VERSION ""

NS_ :

BS_ :

BU_: Charger BMS

BO_ 2551207668 BCL: 5 BMS
 SG_ CurrentDemand : 16|16@1- (1.0,0.0) [-32768.0|32767.0] "" Charger
 SG_ VoltageDemand : 0|16@1- (1.0,0.0) [-32768.0|32767.0] "" Charger

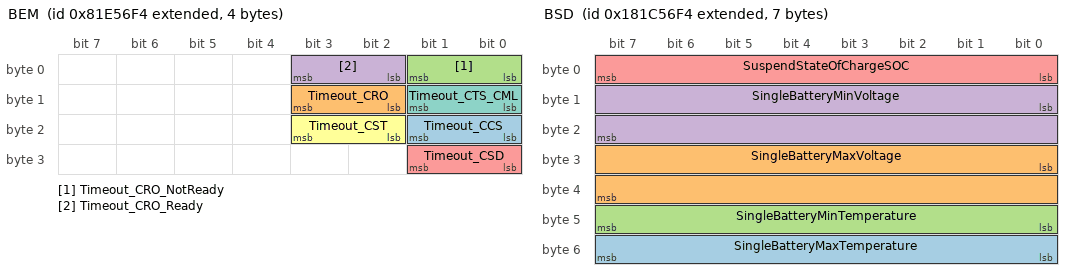
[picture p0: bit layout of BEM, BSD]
BO_ 2283689716 BEM: 4 BMS
 SG_ Timeout_CCS : 16|2@1- (1.0,0.0) [-2.0|1.0] "" Charger
 SG_ Timeout_CRO : 10|2@1- (1.0,0.0) [-2.0|1.0] "" Charger
 SG_ Timeout_CRO_NotReady : 0|2@1- (1.0,0.0) [-2.0|1.0] "" Charger
 SG_ Timeout_CRO_Ready : 2|2@1- (1.0,0.0) [-2.0|1.0] "" Charger
 SG_ Timeout_CSD : 24|2@1- (1.0,0.0) [-2.0|1.0] "" Charger
 SG_ Timeout_CST : 18|2@1- (1.0,0.0) [-2.0|1.0] "" Charger
 SG_ Timeout_CTS_CML : 8|2@1- (1.0,0.0) [-2.0|1.0] "" Charger

BO_ 2552714996 BHM: 2 BMS
 SG_ MaxChargingVoltage : 0|16@1- (1.0,0.0) [-32768.0|32767.0] "" Charger

BO_ 2416531188 BRO: 1 BMS
 SG_ BmsReadyForCharging : 0|8@1- (1.0,0.0) [-128.0|127.0] "" Charger

BO_ 2551994100 BSD: 7 BMS
 SG_ SingleBatteryMaxTemperature : 48|8@1- (1.0,0.0) [-128.0|127.0] "" Charger
 SG_ SingleBatteryMaxVoltage : 24|16@1- (1.0,0.0) [-32768.0|32767.0] "" Charger
 SG_ SingleBatteryMinTemperature : 40|8@1- (1.0,0.0) [-128.0|127.0] "" Charger
 SG_ SingleBatteryMinVoltage : 8|16@1- (1.0,0.0) [-32768.0|32767.0] "" Charger
 SG_ SuspendStateOfChargeSOC : 0|8@1- (1.0,0.0) [-128.0|127.0] "" Charger

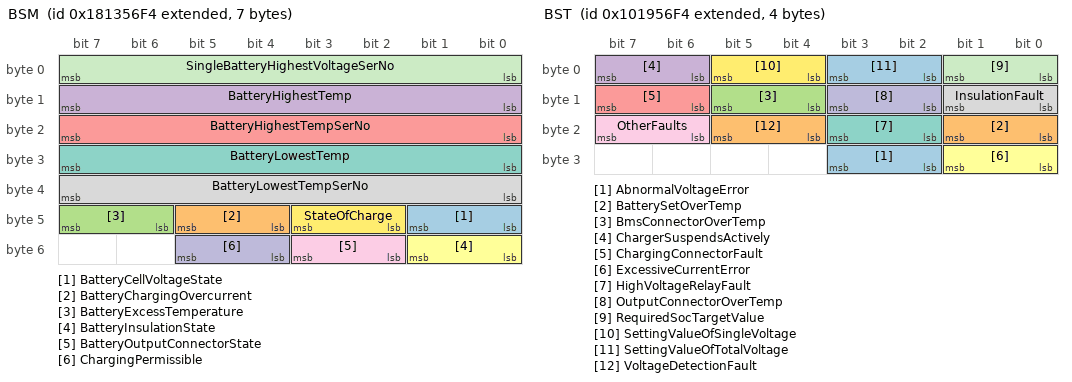
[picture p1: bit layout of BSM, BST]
BO_ 2551404276 BSM: 7 BMS
 SG_ BatteryCellVoltageState : 40|2@1- (1.0,0.0) [-2.0|1.0] "" Charger
 SG_ BatteryChargingOvercurrent : 44|2@1- (1.0,0.0) [-2.0|1.0] "" Charger
 SG_ BatteryExcessTemperature : 46|2@1- (1.0,0.0) [-2.0|1.0] "" Charger
 SG_ BatteryHighestTemp : 8|8@1- (1.0,0.0) [-128.0|127.0] "" Charger
 SG_ BatteryHighestTempSerNo : 16|8@1- (1.0,0.0) [-128.0|127.0] "" Charger
 SG_ BatteryInsulationState : 48|2@1- (1.0,0.0) [-2.0|1.0] "" Charger
 SG_ BatteryLowestTemp : 24|8@1- (1.0,0.0) [-128.0|127.0] "" Charger
 SG_ BatteryLowestTempSerNo : 32|8@1- (1.0,0.0) [-128.0|127.0] "" Charger
 SG_ BatteryOutputConnectorState : 50|2@1- (1.0,0.0) [-2.0|1.0] "" Charger
 SG_ ChargingPermissible : 52|2@1- (1.0,0.0) [-2.0|1.0] "" Charger
 SG_ SingleBatteryHighestVoltageSerNo : 0|8@1- (1.0,0.0) [-128.0|127.0] "" Charger
 SG_ StateOfCharge : 42|2@1- (1.0,0.0) [-2.0|1.0] "" Charger

BO_ 2417579764 BST: 4 BMS
 SG_ AbnormalVoltageError : 26|2@1- (1.0,0.0) [-2.0|1.0] "" Charger
 SG_ BatterySetOverTemp : 16|2@1- (1.0,0.0) [-2.0|1.0] "" Charger
 SG_ BmsConnectorOverTemp : 12|2@1- (1.0,0.0) [-2.0|1.0] "" Charger
 SG_ ChargerSuspendsActively : 6|2@1- (1.0,0.0) [-2.0|1.0] "" Charger
 SG_ ChargingConnectorFault : 14|2@1- (1.0,0.0) [-2.0|1.0] "" Charger
 SG_ ExcessiveCurrentError : 24|2@1- (1.0,0.0) [-2.0|1.0] "" Charger
 SG_ HighVoltageRelayFault : 18|2@1- (1.0,0.0) [-2.0|1.0] "" Charger
 SG_ InsulationFault : 8|2@1- (1.0,0.0) [-2.0|1.0] "" Charger
 SG_ OtherFaults : 22|2@1- (1.0,0.0) [-2.0|1.0] "" Charger
 SG_ OutputConnectorOverTemp : 10|2@1- (1.0,0.0) [-2.0|1.0] "" Charger
 SG_ RequiredSocTargetValue : 0|2@1- (1.0,0.0) [-2.0|1.0] "" Charger
 SG_ SettingValueOfSingleVoltage : 4|2@1- (1.0,0.0) [-2.0|1.0] "" Charger
 SG_ SettingValueOfTotalVoltage : 2|2@1- (1.0,0.0) [-2.0|1.0] "" Charger
 SG_ VoltageDetectionFault : 20|2@1- (1.0,0.0) [-2.0|1.0] "" Charger

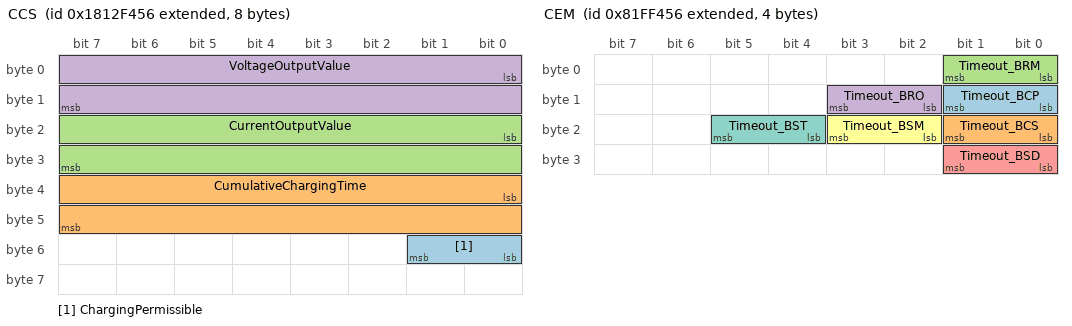
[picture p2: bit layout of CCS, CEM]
BO_ 2551379030 CCS: 8 Charger
 SG_ ChargingPermissible : 48|2@1- (1.0,0.0) [-2.0|1.0] "" BMS
 SG_ CumulativeChargingTime : 32|16@1- (1.0,0.0) [-32768.0|32767.0] "" BMS
 SG_ CurrentOutputValue : 16|16@1- (1.0,0.0) [-32768.0|32767.0] "" BMS
 SG_ VoltageOutputValue : 0|16@1- (1.0,0.0) [-32768.0|32767.0] "" BMS

BO_ 2283795542 CEM: 4 Charger
 SG_ Timeout_BCP : 8|2@1- (1.0,0.0) [-2.0|1.0] "" BMS
 SG_ Timeout_BCS : 16|2@1- (1.0,0.0) [-2.0|1.0] "" BMS
 SG_ Timeout_BRM : 0|2@1- (1.0,0.0) [-2.0|1.0] "" BMS
 SG_ Timeout_BRO : 10|2@1- (1.0,0.0) [-2.0|1.0] "" BMS
 SG_ Timeout_BSD : 24|2@1- (1.0,0.0) [-2.0|1.0] "" BMS
 SG_ Timeout_BSM : 18|2@1- (1.0,0.0) [-2.0|1.0] "" BMS
 SG_ Timeout_BST : 20|2@1- (1.0,0.0) [-2.0|1.0] "" BMS

BO_ 2552689750 CHM: 3 Charger
 SG_ MajorChargerVersion : 8|16@1- (1.0,0.0) [-32768.0|32767.0] "" BMS

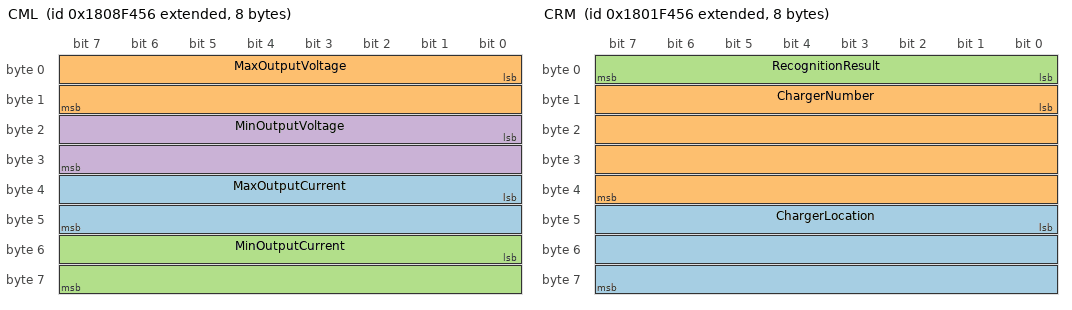
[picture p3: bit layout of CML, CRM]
BO_ 2550723670 CML: 8 Charger
 SG_ MaxOutputCurrent : 32|16@1- (1.0,0.0) [-32768.0|32767.0] "" BMS
 SG_ MaxOutputVoltage : 0|16@1- (1.0,0.0) [-32768.0|32767.0] "" BMS
 SG_ MinOutputCurrent : 48|16@1- (1.0,0.0) [-32768.0|32767.0] "" BMS
 SG_ MinOutputVoltage : 16|16@1- (1.0,0.0) [-32768.0|32767.0] "" BMS

BO_ 2550264918 CRM: 8 Charger
 SG_ ChargerLocation : 40|24@1- (1.0,0.0) [-8388608.0|8388607.0] "" BMS
 SG_ ChargerNumber : 8|32@1- (1.0,0.0) [-2147483648.0|2147483647.0] "" BMS
 SG_ RecognitionResult : 0|8@1- (1.0,0.0) [-128.0|127.0] "" BMS

BO_ 2416637014 CRO: 1 Charger
 SG_ ChargerReadyForCharging : 0|8@1- (1.0,0.0) [-128.0|127.0] "" BMS

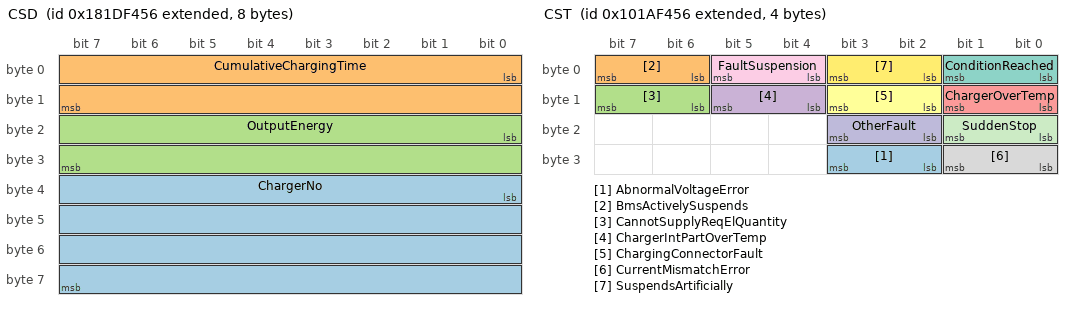
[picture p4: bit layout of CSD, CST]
BO_ 2552099926 CSD: 8 Charger
 SG_ ChargerNo : 32|32@1- (1.0,0.0) [-2147483648.0|2147483647.0] "" BMS
 SG_ CumulativeChargingTime : 0|16@1- (1.0,0.0) [-32768.0|32767.0] "" BMS
 SG_ OutputEnergy : 16|16@1- (1.0,0.0) [-32768.0|32767.0] "" BMS

BO_ 2417685590 CST: 4 Charger
 SG_ AbnormalVoltageError : 26|2@1- (1.0,0.0) [-2.0|1.0] "" BMS
 SG_ BmsActivelySuspends : 6|2@1- (1.0,0.0) [-2.0|1.0] "" BMS
 SG_ CannotSupplyReqElQuantity : 14|2@1- (1.0,0.0) [-2.0|1.0] "" BMS
 SG_ ChargerIntPartOverTemp : 12|2@1- (1.0,0.0) [-2.0|1.0] "" BMS
 SG_ ChargerOverTemp : 8|2@1- (1.0,0.0) [-2.0|1.0] "" BMS
 SG_ ChargingConnectorFault : 10|2@1- (1.0,0.0) [-2.0|1.0] "" BMS
 SG_ ConditionReached : 0|2@1- (1.0,0.0) [-2.0|1.0] "" BMS
 SG_ CurrentMismatchError : 24|2@1- (1.0,0.0) [-2.0|1.0] "" BMS
 SG_ FaultSuspension : 4|2@1- (1.0,0.0) [-2.0|1.0] "" BMS
 SG_ OtherFault : 18|2@1- (1.0,0.0) [-2.0|1.0] "" BMS
 SG_ SuddenStop : 16|2@1- (1.0,0.0) [-2.0|1.0] "" BMS
 SG_ SuspendsArtificially : 2|2@1- (1.0,0.0) [-2.0|1.0] "" BMS

CM_ BO_ 2551207668 "[Charging] Battery charging demand";
CM_ SG_ 2551207668 CurrentDemand "Current demand (A)";
CM_ SG_ 2551207668 VoltageDemand "Voltage demand (V)";
CM_ BO_ 2283689716 "[Error] BMS's error message";
CM_ SG_ 2283689716 Timeout_CCS "Timeout  of  charger's  charging  state  message";
CM_ SG_ 2283689716 Timeout_CRO "Timeout of charger's charging preparation completion message";
CM_ SG_ 2283689716 Timeout_CRO_NotReady "Timeout of CRO with SPN2560=0×00";
CM_ SG_ 2283689716 Timeout_CRO_Ready "Timeout of CRO with SPN2560=0×AA";
CM_ SG_ 2283689716 Timeout_CSD "Timeout of charger's charging statistics message";
CM_ SG_ 2283689716 Timeout_CST "Timeout of charger's charging suspension message";
CM_ SG_ 2283689716 Timeout_CTS_CML "Timeout of charger time synchronization message and charger maximum output capacity message";
CM_ BO_ 2552714996 "[Handshake Initiation] Vehicle handshake";
CM_ SG_ 2552714996 MaxChargingVoltage "Total maximum permissible charging voltage";
CM_ BO_ 2416531188 "[Parameter Configuration] Battery charging ready state";
CM_ SG_ 2416531188 BmsReadyForCharging "Whether BMS is ready for charging";
CM_ BO_ 2551994100 "[EndOfCharging] BMS statistical data";
CM_ SG_ 2551994100 SingleBatteryMaxTemperature "Maximum temperature of power storage battery (°C)";
CM_ SG_ 2551994100 SingleBatteryMaxVoltage "Maximum voltage of single power storage battery (V)";
CM_ SG_ 2551994100 SingleBatteryMinTemperature "Minimum temperature of power storage battery (°C)";
CM_ SG_ 2551994100 SingleBatteryMinVoltage "Minimum voltage of single power storage battery (V)";
CM_ SG_ 2551994100 SuspendStateOfChargeSOC "Suspend state-of-charge SOC (%)";
CM_ BO_ 2551404276 "[Charging] Power storage battery status information";
CM_ SG_ 2551404276 BatteryCellVoltageState "Voltage state of battery cell";
CM_ SG_ 2551404276 BatteryChargingOvercurrent "Charging overcurrent of power storage battery";
CM_ SG_ 2551404276 BatteryExcessTemperature "Excess temperature of power storage battery";
CM_ SG_ 2551404276 BatteryHighestTemp "Highest temperature of power storage battery";
CM_ SG_ 2551404276 BatteryHighestTempSerNo "Serial number of the highest temperature detection point";
CM_ SG_ 2551404276 BatteryInsulationState "Insulation state of power storage battery";
CM_ SG_ 2551404276 BatteryLowestTemp "The lowest temperature of power storage battery";
CM_ SG_ 2551404276 BatteryLowestTempSerNo "Serial number of the lowest temperature detection point of power storage battery";
CM_ SG_ 2551404276 BatteryOutputConnectorState "Connection state of output connector of power storage battery set";
CM_ SG_ 2551404276 ChargingPermissible "Charging permissible";
CM_ SG_ 2551404276 SingleBatteryHighestVoltageSerNo "Serial number of the highest voltage of single power storage battery";
CM_ SG_ 2551404276 StateOfCharge "State-of-charge SOC of power storage battery for complete vehicle";
CM_ BO_ 2417579764 "[Charging] BMS suspending charging";
CM_ SG_ 2417579764 AbnormalVoltageError "Whether voltage is abnormal";
CM_ SG_ 2417579764 BatterySetOverTemp "Battery set over-temperature";
CM_ SG_ 2417579764 BmsConnectorOverTemp "BMS component and output connector over-temperature";
CM_ SG_ 2417579764 ChargerSuspendsActively "Wether charger actively suspends";
CM_ SG_ 2417579764 ChargingConnectorFault "Charging connector fault";
CM_ SG_ 2417579764 ExcessiveCurrentError "Whether current exceeds the demand value";
CM_ SG_ 2417579764 HighVoltageRelayFault "High voltage relay fault";
CM_ SG_ 2417579764 InsulationFault "Wether insulation fault";
CM_ SG_ 2417579764 OtherFaults "Other faults";
CM_ SG_ 2417579764 OutputConnectorOverTemp "Output connector over-temperature";
CM_ SG_ 2417579764 RequiredSocTargetValue "Wether the required SOC target value reached";
CM_ SG_ 2417579764 SettingValueOfSingleVoltage "Wether the setting value of single voltage reached";
CM_ SG_ 2417579764 SettingValueOfTotalVoltage "Wether the setting value of total voltage reached";
CM_ SG_ 2417579764 VoltageDetectionFault "Voltage detection fault at check point 2";
CM_ BO_ 2551379030 "[Charging] Charger's charging status";
CM_ SG_ 2551379030 ChargingPermissible "Charging permissible";
CM_ SG_ 2551379030 CumulativeChargingTime "Cumulative charging time (min)";
CM_ SG_ 2551379030 CurrentOutputValue "Current output value (A)";
CM_ SG_ 2551379030 VoltageOutputValue "Voltage output value (V)";
CM_ BO_ 2283795542 "[Error] Charger's error message";
CM_ SG_ 2283795542 Timeout_BCP "Timeout of battery charging parameter message";
CM_ SG_ 2283795542 Timeout_BCS "Timeout of overall battery charging state message";
CM_ SG_ 2283795542 Timeout_BRM "Timeout of BMS and vehicle recognition message";
CM_ SG_ 2283795542 Timeout_BRO "Timeout of BMS's charging preparation completion message";
CM_ SG_ 2283795542 Timeout_BSD "Timeout of BMS's charging statistics message";
CM_ SG_ 2283795542 Timeout_BSM "Timeout of battery charging requirement message";
CM_ SG_ 2283795542 Timeout_BST "Timeout of BMS's charging suspension message";
CM_ BO_ 2552689750 "[Handshake Initiation] Charger handshake";
CM_ BO_ 2550723670 "[Parameter Configuration] Charger's maximum output";
CM_ SG_ 2550723670 MaxOutputCurrent "Maximum output current (A)";
CM_ SG_ 2550723670 MaxOutputVoltage "Maximum output voltage (V)";
CM_ SG_ 2550723670 MinOutputCurrent "Minimum output current (A)";
CM_ SG_ 2550723670 MinOutputVoltage "Minimum output voltage (V)";
CM_ BO_ 2550264918 "[Handshake Recognition] Charger recognition";
CM_ SG_ 2550264918 ChargerLocation "Charger/charging station location code";
CM_ SG_ 2550264918 ChargerNumber "Charger Number";
CM_ SG_ 2550264918 RecognitionResult "Recognition  result";
CM_ BO_ 2416637014 "[Parameter Configuration] Charger output ready state";
CM_ SG_ 2416637014 ChargerReadyForCharging "Whether charger is ready for charging";
CM_ BO_ 2552099926 "[EndOfCharging] Charger's statistical data";
CM_ SG_ 2552099926 ChargerNo "Charger No.";
CM_ SG_ 2552099926 CumulativeChargingTime "Cumulative charging time (min)";
CM_ SG_ 2552099926 OutputEnergy "Output energy";
CM_ BO_ 2417685590 "[Charging] Charger suspending charging";
CM_ SG_ 2417685590 AbnormalVoltageError "Voltage is abnormal";
CM_ SG_ 2417685590 BmsActivelySuspends "BMS actively suspends charging";
CM_ SG_ 2417685590 CannotSupplyReqElQuantity "The required electric quantity cannot be transmitted";
CM_ SG_ 2417685590 ChargerIntPartOverTemp "Charger is over-temperature at the internal part";
CM_ SG_ 2417685590 ChargerOverTemp "Charging suspended: charger over-temperature";
CM_ SG_ 2417685590 ChargingConnectorFault "Charging suspended: charging connector fault";
CM_ SG_ 2417685590 ConditionReached "Charging suspends due to reaching the condition set by charger";
CM_ SG_ 2417685590 CurrentMismatchError "Current mismatching";
CM_ SG_ 2417685590 FaultSuspension "Charging fault suspension";
CM_ SG_ 2417685590 OtherFault "Other fault";
CM_ SG_ 2417685590 SuddenStop "Sudden stop of charger";
CM_ SG_ 2417685590 SuspendsArtificially "Charging suspends artificially";
BA_DEF_ BO_  "GenMsgSendType" ENUM "cyclic","reserved","cyclicIfActive","reserved","reserved","reserved","reserved","reserved","noMsgSendType";
BA_DEF_ BO_  "GenMsgCycleTime" INT 0 250;
BA_ "GenMsgSendType" BO_ 2551207668 0;
BA_ "GenMsgCycleTime" BO_ 2551207668 50;
BA_ "GenMsgSendType" BO_ 2283689716 0;
BA_ "GenMsgCycleTime" BO_ 2283689716 250;
BA_ "GenMsgSendType" BO_ 2552714996 0;
BA_ "GenMsgCycleTime" BO_ 2552714996 250;
BA_ "GenMsgSendType" BO_ 2416531188 0;
BA_ "GenMsgCycleTime" BO_ 2416531188 250;
BA_ "GenMsgSendType" BO_ 2551994100 0;
BA_ "GenMsgCycleTime" BO_ 2551994100 250;
BA_ "GenMsgSendType" BO_ 2551404276 0;
BA_ "GenMsgCycleTime" BO_ 2551404276 250;
BA_ "GenMsgSendType" BO_ 2417579764 0;
BA_ "GenMsgCycleTime" BO_ 2417579764 10;
BA_ "GenMsgSendType" BO_ 2551379030 0;
BA_ "GenMsgCycleTime" BO_ 2551379030 50;
BA_ "GenMsgSendType" BO_ 2283795542 0;
BA_ "GenMsgCycleTime" BO_ 2283795542 250;
BA_ "GenMsgSendType" BO_ 2552689750 0;
BA_ "GenMsgCycleTime" BO_ 2552689750 250;
BA_ "GenMsgSendType" BO_ 2550723670 0;
BA_ "GenMsgCycleTime" BO_ 2550723670 250;
BA_ "GenMsgSendType" BO_ 2550264918 0;
BA_ "GenMsgCycleTime" BO_ 2550264918 250;
BA_ "GenMsgSendType" BO_ 2416637014 0;
BA_ "GenMsgCycleTime" BO_ 2416637014 250;
BA_ "GenMsgSendType" BO_ 2552099926 0;
BA_ "GenMsgCycleTime" BO_ 2552099926 250;
BA_ "GenMsgSendType" BO_ 2417685590 0;
BA_ "GenMsgCycleTime" BO_ 2417685590 10;
